VERSION ""

NS_ :

BS_:

BU_: TESTER XB_SUP_F XB_SUP_D XB_SUP_E

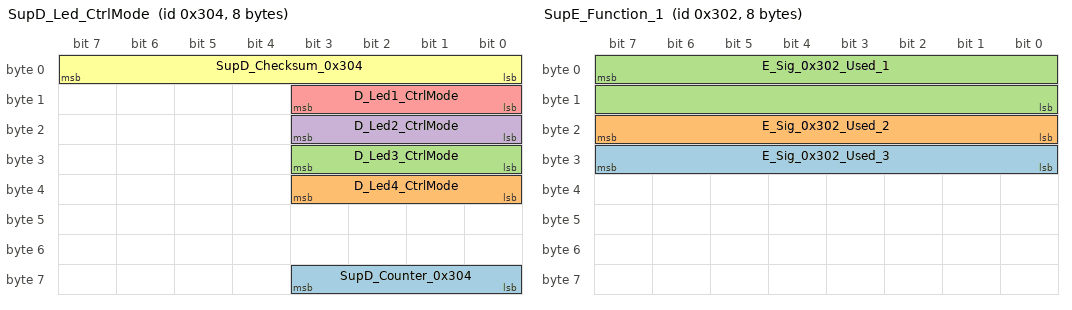
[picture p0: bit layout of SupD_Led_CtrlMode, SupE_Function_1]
BO_ 772 SupD_Led_CtrlMode: 8 XB_SUP_D
 SG_ SupD_Counter_0x304 : 59|4@0+ (1,0) [0|14] ""  XB_SUP_F
 SG_ D_Led4_CtrlMode : 35|4@0+ (1,0) [0|2] ""  XB_SUP_F
 SG_ D_Led3_CtrlMode : 27|4@0+ (1,0) [0|2] ""  XB_SUP_F
 SG_ D_Led2_CtrlMode : 19|4@0+ (1,0) [0|2] ""  XB_SUP_F
 SG_ D_Led1_CtrlMode : 11|4@0+ (1,0) [0|2] ""  XB_SUP_F
 SG_ SupD_Checksum_0x304 : 7|8@0+ (1,0) [0|255] ""  XB_SUP_F

BO_ 770 SupE_Function_1: 8 XB_SUP_E
 SG_ E_Sig_0x302_Used_3 : 31|8@0+ (1,0) [0|4095] ""  XB_SUP_F
 SG_ E_Sig_0x302_Used_2 : 23|8@0+ (1,0) [0|4095] ""  XB_SUP_F
 SG_ E_Sig_0x302_Used_1 : 7|16@0+ (1,0) [0|65535] ""  XB_SUP_F

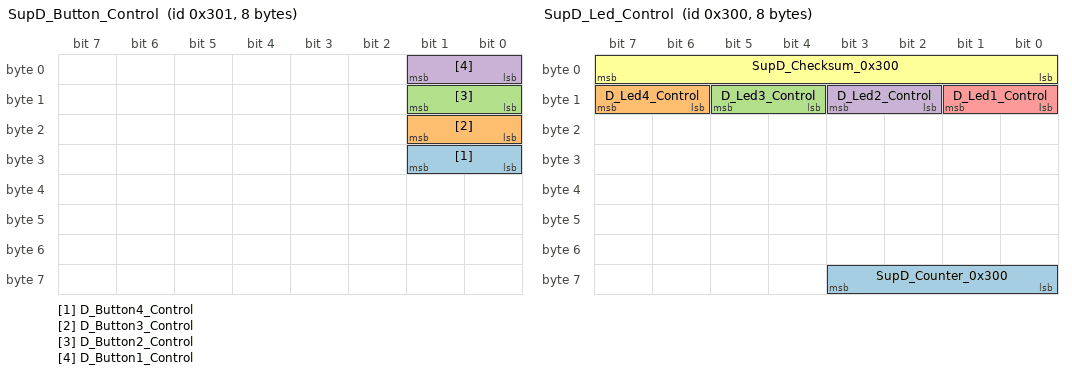
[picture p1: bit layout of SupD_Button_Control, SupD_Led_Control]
BO_ 769 SupD_Button_Control: 8 XB_SUP_D
 SG_ D_Button4_Control : 25|2@0+ (1,0) [0|2] ""  XB_SUP_F
 SG_ D_Button3_Control : 17|2@0+ (1,0) [0|2] ""  XB_SUP_F
 SG_ D_Button2_Control : 9|2@0+ (1,0) [0|2] ""  XB_SUP_F
 SG_ D_Button1_Control : 1|2@0+ (1,0) [0|2] ""  XB_SUP_F

BO_ 768 SupD_Led_Control: 8 XB_SUP_D
 SG_ SupD_Counter_0x300 : 59|4@0+ (1,0) [0|14] ""  XB_SUP_F
 SG_ D_Led4_Control : 15|2@0+ (1,0) [0|3] ""  XB_SUP_F
 SG_ D_Led3_Control : 13|2@0+ (1,0) [0|3] ""  XB_SUP_F
 SG_ D_Led2_Control : 11|2@0+ (1,0) [0|3] ""  XB_SUP_F
 SG_ D_Led1_Control : 9|2@0+ (1,0) [0|3] ""  XB_SUP_F
 SG_ SupD_Checksum_0x300 : 7|8@0+ (1,0) [0|255] ""  XB_SUP_F

BO_ 534 SupF_ComError: 8 XB_SUP_F
 SG_ F_Meg_E2E_Error : 15|8@0+ (1,0) [0|255] ""  XB_SUP_D
 SG_ F_Mes_Lost_Error : 7|8@0+ (1,0) [0|255] ""  XB_SUP_D

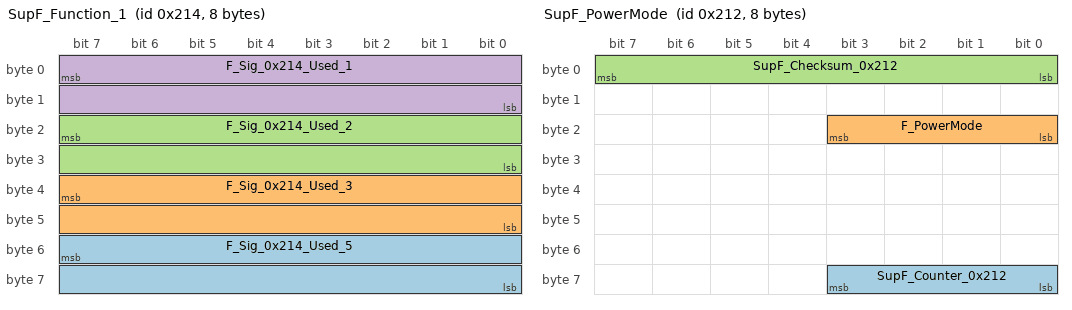
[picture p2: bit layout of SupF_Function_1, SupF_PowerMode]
BO_ 532 SupF_Function_1: 8 XB_SUP_F
 SG_ F_Sig_0x214_Used_5 : 55|16@0+ (1,0) [0|65535] ""  XB_SUP_D
 SG_ F_Sig_0x214_Used_3 : 39|16@0+ (1,0) [0|65535] ""  XB_SUP_D
 SG_ F_Sig_0x214_Used_2 : 23|16@0+ (1,0) [0|65535] ""  XB_SUP_D
 SG_ F_Sig_0x214_Used_1 : 7|16@0+ (1,0) [0|65535] ""  XB_SUP_D

BO_ 531 SupF_Angle: 8 XB_SUP_F
 SG_ F_AAA_Angle : 7|8@0+ (0.5,-10) [-10|10] "o"  XB_SUP_D

BO_ 530 SupF_PowerMode: 8 XB_SUP_F
 SG_ SupF_Counter_0x212 : 59|4@0+ (1,0) [0|14] ""  XB_SUP_D
 SG_ F_PowerMode : 19|4@0+ (1,0) [0|7] ""  XB_SUP_D
 SG_ SupF_Checksum_0x212 : 7|8@0+ (1,0) [0|255] ""  XB_SUP_D

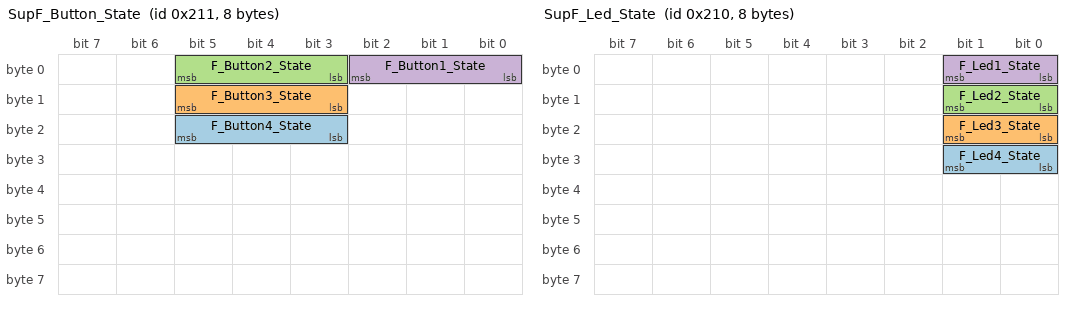
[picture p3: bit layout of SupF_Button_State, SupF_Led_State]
BO_ 529 SupF_Button_State: 8 XB_SUP_F
 SG_ F_Button4_State : 21|3@0+ (1,0) [0|7] ""  XB_SUP_D
 SG_ F_Button3_State : 13|3@0+ (1,0) [0|7] ""  XB_SUP_D
 SG_ F_Button2_State : 5|3@0+ (1,0) [0|7] ""  XB_SUP_D
 SG_ F_Button1_State : 2|3@0+ (1,0) [0|7] ""  XB_SUP_D

BO_ 528 SupF_Led_State: 8 XB_SUP_F
 SG_ F_Led4_State : 25|2@0+ (1,0) [0|3] ""  XB_SUP_D
 SG_ F_Led3_State : 17|2@0+ (1,0) [0|3] ""  XB_SUP_D
 SG_ F_Led2_State : 9|2@0+ (1,0) [0|3] ""  XB_SUP_D
 SG_ F_Led1_State : 1|2@0+ (1,0) [0|3] ""  XB_SUP_D

BO_ 1537 Meg_NmTx: 8 XB_SUP_F
 SG_ Sig_NmTx_Nid : 7|8@0+ (1,0) [0|255] ""  TESTER

BO_ 1536 Meg_NmRx: 8 TESTER
 SG_ Sig_NmRx_Nid : 7|8@0+ (1,0) [0|255] ""  XB_SUP_F

BO_ 1873 Meg_ResDiag: 8 XB_SUP_F
 SG_ Sig_ResDiag : 7|64@0+ (1,0) [0|255] ""  TESTER

BO_ 1793 Meg_PhyDiag: 8 TESTER
 SG_ Sig_PhyDiag : 7|64@0+ (1,0) [0|255] ""  XB_SUP_F

BO_ 2015 Meg_FunDiag: 8 TESTER
 SG_ Sig_FunDiag : 7|64@0+ (1,0) [0|255] ""  XB_SUP_F

BA_DEF_ BU_  "TimeQuantaCANFDMax" INT 4 257;
BA_DEF_ BU_  "TimeQuantaCANFDMin" INT 4 257;
BA_DEF_ BU_  "TimeQuantaMax" INT 4 257;
BA_DEF_ BU_  "TimeQuantaMin" INT 4 257;
BA_DEF_ BU_  "SSPOffsetCANFDMax" FLOAT 50 99.9;
BA_DEF_ BU_  "SSPOffsetCANFDMin" FLOAT 50 99.9;
BA_DEF_ BU_  "SamplePointCANFDMax" FLOAT 50 99.9;
BA_DEF_ BU_  "SamplePointCANFDMin" FLOAT 50 99.9;
BA_DEF_ BU_  "SyncJumpWidthCANFDMax" FLOAT 0 50;
BA_DEF_ BU_  "SyncJumpWidthCANFDMin" FLOAT 0 50;
BA_DEF_  "BaudrateCANFD" INT 1 16000000;
BA_DEF_ SG_  "GenSigSwitchedByIgnition" ENUM  "No","Yes";
BA_DEF_ SG_  "GenSigFuncType" ENUM  "NoFunction","MsgCounter","CRC-8","XOR","XOR-2","DatedBit","SW-Kl15","CHK","Constant","Protocol","CRC-8-SAE_J1850","CRC-32","DataLength","DataID","MsgCounter16","SOK-Signatur","Cluster";
BA_DEF_ BO_  "MsgType" ENUM  "Application","NM ","NMH","TP2.0","ISO-TP ","BAP","EID","KS","XCP_PRE_CONFIGURED","XCP_RUNTIME_CONFIGURED";
BA_DEF_ BO_  "NmhMessage" ENUM  "No","Yes";
BA_DEF_ BO_  "NmMessage" ENUM  "No","Yes";
BA_DEF_ BO_  "GenMsgNrOfRepetition" INT 0 100;
BA_DEF_ BU_  "NmStationAddress" HEX 0 127;
BA_DEF_ BU_  "NmhNode" ENUM  "No","Yes";
BA_DEF_ BU_  "ECUVariantDefault" ENUM  "No","Yes";
BA_DEF_ BU_  "GenNodAutoGenSnd" ENUM  "No","Yes";
BA_DEF_ BU_  "GenNodAutoGenDsp" ENUM  "No","Yes";
BA_DEF_  "NmhLongTimer" INT 0 65535;
BA_DEF_  "NmhPrepareBusSleepTimer" INT 0 65535;
BA_DEF_  "NmhWaitBusSleepTimer" INT 0 65535;
BA_DEF_  "NmhTimeoutTimer" INT 0 65535;
BA_DEF_  "NBTMax" INT 1 30;
BA_DEF_  "NBTMin" INT 1 30;
BA_DEF_  "SyncJumpWidthMax" INT 1 4;
BA_DEF_  "SyncJumpWidthMin" INT 1 4;
BA_DEF_  "SamplePointMax" INT 1 100;
BA_DEF_  "SamplePointMin" INT 1 100;
BA_DEF_  "Baudrate" INT 1 1000000;
BA_DEF_  "VersionYear" INT 0 99;
BA_DEF_  "VersionWeek" INT 1 52;
BA_DEF_  "VersionMonth" INT 1 12;
BA_DEF_  "VersionDay" INT 1 31;
BA_DEF_  "NmhMessageCount" INT 0 1024;
BA_DEF_  "NmhBaseAddress" HEX 1536 1663;
BA_DEF_  "Manufacturer" STRING ;
BA_DEF_  "DBName" STRING ;
BA_DEF_  "BusType" STRING ;
BA_DEF_  "GenEnvVarEndingDsp" STRING ;
BA_DEF_  "GenEnvVarEndingSnd" STRING ;
BA_DEF_  "GenEnvVarPrefix" STRING ;
BA_DEF_  "GenNWMApBusSleep" STRING ;
BA_DEF_  "GenNWMApCanNormal" STRING ;
BA_DEF_  "GenNWMApCanOff" STRING ;
BA_DEF_  "GenNWMApCanOn" STRING ;
BA_DEF_  "GenNWMApCanSleep" STRING ;
BA_DEF_  "GenNWMApCanWakeUp" STRING ;
BA_DEF_  "GenNWMGotoMode_Awake" STRING ;
BA_DEF_  "GenNWMGotoMode_BusSleep" STRING ;
BA_DEF_  "GenNWMTalkNM" STRING ;
BA_DEF_ BU_  "NodeLayerModules" STRING ;
BA_DEF_ BU_  "ILUsed" ENUM  "No","Yes";
BA_DEF_ BO_  "DiagState" ENUM  "No","Yes";
BA_DEF_ BO_  "DiagResponse" ENUM  "No","Yes";
BA_DEF_ BO_  "DiagRequest" ENUM  "No","Yes";
BA_DEF_ BO_  "GenMsgILSupport" ENUM  "No","Yes";
BA_DEF_ BO_  "GenMsgCycleTime" INT 0 65535;
BA_DEF_ BO_  "GenMsgMinAcceptLength" INT 0 8;
BA_DEF_ BO_  "GenMsgSendType" ENUM  "Cyclic","CyclicAndSpontanX","Event";
BA_DEF_ BO_  "CANFD_BRS" ENUM  "0","1";
BA_DEF_ BO_  "VFrameFormat" ENUM  "StandardCAN","ExtendedCAN","reserved","reserved","reserved","reserved","reserved","reserved","reserved","reserved","reserved","reserved","reserved","reserved","StandardCAN_FD","ExtendedCAN_FD";
BA_DEF_ SG_  "GenSigEnvVarType" ENUM  "undef","int","float";
BA_DEF_ SG_  "GenSigSendType" ENUM  "Cyclic","OnWrite","OnWriteWithRepetition","OnChange","OnChangeWithRepetition","IfActive","IfActiveWithRepetition","NoSigSendType","NotUsed","NotUsed","NotUsed","NotUsed","NotUsed";
BA_DEF_ SG_  "GenSigStartValue" FLOAT 0 1215752192;
BA_DEF_DEF_  "TimeQuantaCANFDMax" 40;
BA_DEF_DEF_  "TimeQuantaCANFDMin" 40;
BA_DEF_DEF_  "TimeQuantaMax" 160;
BA_DEF_DEF_  "TimeQuantaMin" 160;
BA_DEF_DEF_  "SSPOffsetCANFDMax" 75;
BA_DEF_DEF_  "SSPOffsetCANFDMin" 75;
BA_DEF_DEF_  "SamplePointCANFDMax" 75;
BA_DEF_DEF_  "SamplePointCANFDMin" 75;
BA_DEF_DEF_  "SyncJumpWidthCANFDMax" 50;
BA_DEF_DEF_  "SyncJumpWidthCANFDMin" 50;
BA_DEF_DEF_  "BaudrateCANFD" 2000000;
BA_DEF_DEF_  "GenSigSwitchedByIgnition" "Yes";
BA_DEF_DEF_  "GenSigFuncType" "NoFunction";
BA_DEF_DEF_  "MsgType" "Application";
BA_DEF_DEF_  "NmhMessage" "No";
BA_DEF_DEF_  "NmMessage" "No";
BA_DEF_DEF_  "GenMsgNrOfRepetition" 0;
BA_DEF_DEF_  "NmStationAddress" 0;
BA_DEF_DEF_  "NmhNode" "Yes";
BA_DEF_DEF_  "ECUVariantDefault" "Yes";
BA_DEF_DEF_  "GenNodAutoGenSnd" "Yes";
BA_DEF_DEF_  "GenNodAutoGenDsp" "Yes";
BA_DEF_DEF_  "NmhLongTimer" 0;
BA_DEF_DEF_  "NmhPrepareBusSleepTimer" 2000;
BA_DEF_DEF_  "NmhWaitBusSleepTimer" 5000;
BA_DEF_DEF_  "NmhTimeoutTimer" 2000;
BA_DEF_DEF_  "NBTMax" 20;
BA_DEF_DEF_  "NBTMin" 10;
BA_DEF_DEF_  "SyncJumpWidthMax" 1;
BA_DEF_DEF_  "SyncJumpWidthMin" 1;
BA_DEF_DEF_  "SamplePointMax" 1;
BA_DEF_DEF_  "SamplePointMin" 1;
BA_DEF_DEF_  "Baudrate" 500000;
BA_DEF_DEF_  "VersionYear" 19;
BA_DEF_DEF_  "VersionWeek" 45;
BA_DEF_DEF_  "VersionMonth" 11;
BA_DEF_DEF_  "VersionDay" 8;
BA_DEF_DEF_  "NmhMessageCount" 1;
BA_DEF_DEF_  "NmhBaseAddress" 1536;
BA_DEF_DEF_  "Manufacturer" "GWM";
BA_DEF_DEF_  "DBName" "V51EV_for_PT_CANFD V1_0婵炲瓨鍤庨崐鏍绮婇敃鍌涘亱";
BA_DEF_DEF_  "BusType" "";
BA_DEF_DEF_  "GenEnvVarEndingDsp" "_d";
BA_DEF_DEF_  "GenEnvVarEndingSnd" "_s";
BA_DEF_DEF_  "GenEnvVarPrefix" "c";
BA_DEF_DEF_  "GenNWMApBusSleep" "apBusSleep()";
BA_DEF_DEF_  "GenNWMApCanNormal" "apCanNormal()";
BA_DEF_DEF_  "GenNWMApCanOff" "apCanOff()";
BA_DEF_DEF_  "GenNWMApCanOn" "apCanOn()";
BA_DEF_DEF_  "GenNWMApCanSleep" "apCanSleep()";
BA_DEF_DEF_  "GenNWMApCanWakeUp" "apCanWakeUp()";
BA_DEF_DEF_  "GenNWMGotoMode_Awake" "GotoMode_Awake()";
BA_DEF_DEF_  "GenNWMGotoMode_BusSleep" "GotoMode_BusSleep()";
BA_DEF_DEF_  "GenNWMTalkNM" "TalkNM()";
BA_DEF_DEF_  "NodeLayerModules" "CANoeILNLVector.dll";
BA_DEF_DEF_  "ILUsed" "Yes";
BA_DEF_DEF_  "DiagState" "No";
BA_DEF_DEF_  "DiagResponse" "No";
BA_DEF_DEF_  "DiagRequest" "No";
BA_DEF_DEF_  "GenMsgILSupport" "Yes";
BA_DEF_DEF_  "GenMsgCycleTime" 10;
BA_DEF_DEF_  "GenMsgMinAcceptLength" 8;
BA_DEF_DEF_  "GenMsgSendType" "Cyclic";
BA_DEF_DEF_  "CANFD_BRS" "1";
BA_DEF_DEF_  "VFrameFormat" "StandardCAN";
BA_DEF_DEF_  "GenSigEnvVarType" "undef";
BA_DEF_DEF_  "GenSigSendType" "Cyclic";
BA_DEF_DEF_  "GenSigStartValue" 0;
BA_ "BusType" "CAN";
BA_ "NmhMessageCount" 256;
BA_ "SyncJumpWidthMin" 2;
BA_ "SyncJumpWidthMax" 4;
BA_ "NmhWaitBusSleepTimer" 2000;
BA_ "NmhPrepareBusSleepTimer" 100;
BA_ "NmhLongTimer" 200;
BA_ "DBName" "DBCNetWork";
BA_ "NmStationAddress" BU_ XB_SUP_F 1;
BA_ "GenMsgNrOfRepetition" BO_ 532 3;
BA_ "GenMsgSendType" BO_ 532 2;
BA_ "GenMsgCycleTime" BO_ 532 20;
BA_ "GenMsgCycleTime" BO_ 530 100;
BA_ "GenMsgCycleTime" BO_ 529 50;
BA_ "GenMsgCycleTime" BO_ 528 100;
BA_ "GenMsgILSupport" BO_ 1537 0;
BA_ "NmMessage" BO_ 1537 1;
BA_ "MsgType" BO_ 1537 1;
BA_ "GenMsgSendType" BO_ 1537 2;
BA_ "GenMsgCycleTime" BO_ 1537 0;
BA_ "NmhMessage" BO_ 1537 1;
BA_ "GenMsgILSupport" BO_ 1536 0;
BA_ "NmMessage" BO_ 1536 1;
BA_ "MsgType" BO_ 1536 1;
BA_ "GenMsgSendType" BO_ 1536 2;
BA_ "GenMsgCycleTime" BO_ 1536 0;
BA_ "NmhMessage" BO_ 1536 1;
BA_ "GenMsgILSupport" BO_ 1873 0;
BA_ "DiagResponse" BO_ 1873 1;
BA_ "MsgType" BO_ 1873 4;
BA_ "GenMsgSendType" BO_ 1873 2;
BA_ "GenMsgCycleTime" BO_ 1873 0;
BA_ "GenMsgILSupport" BO_ 1793 0;
BA_ "DiagRequest" BO_ 1793 1;
BA_ "MsgType" BO_ 1793 4;
BA_ "GenMsgSendType" BO_ 1793 2;
BA_ "GenMsgCycleTime" BO_ 1793 0;
BA_ "GenMsgILSupport" BO_ 2015 0;
BA_ "DiagState" BO_ 2015 1;
BA_ "MsgType" BO_ 2015 4;
BA_ "GenMsgSendType" BO_ 2015 2;
BA_ "GenMsgCycleTime" BO_ 2015 0;
BA_ "GenSigStartValue" SG_ 768 D_Led4_Control 2;
BA_ "GenSigStartValue" SG_ 768 D_Led3_Control 2;
BA_ "GenSigStartValue" SG_ 768 D_Led2_Control 2;
BA_ "GenSigStartValue" SG_ 768 D_Led1_Control 2;
BA_ "GenSigStartValue" SG_ 531 F_AAA_Angle 36;
VAL_ 772 D_Led4_CtrlMode 0 "Can_Control" 1 "Button_Control_Mode1" 2 "Button_Control_Mode2" 3 "Reserve" ;
VAL_ 772 D_Led3_CtrlMode 0 "Can_Control" 1 "Button_Control_Mode1" 2 "Button_Control_Mode2" 3 "Reserve" ;
VAL_ 772 D_Led2_CtrlMode 0 "Can_Control" 1 "Button_Control_Mode1" 2 "Button_Control_Mode2" 3 "Reserve" ;
VAL_ 772 D_Led1_CtrlMode 0 "Can_Control" 1 "Button_Control_Mode1" 2 "Button_Control_Mode2" 3 "Reserve" ;
VAL_ 769 D_Button4_Control 0 "Button_Mode1" 1 "Button_Mode2" 2 "Button_Disable" ;
VAL_ 769 D_Button3_Control 0 "Button_Mode1" 1 "Button_Mode2" 2 "Button_Disable" ;
VAL_ 769 D_Button2_Control 0 "Button_Mode1" 1 "Button_Mode2" 2 "Button_Disable" ;
VAL_ 769 D_Button1_Control 0 "Button_Mode1" 1 "Button_Mode2" 2 "Button_Disable" ;
VAL_ 768 D_Led4_Control 0 "Init" 1 "LED_ON" 2 "LED_OFF" 3 "Reserve" ;
VAL_ 768 D_Led3_Control 0 "Init" 1 "LED_ON" 2 "LED_OFF" 3 "Reserve" ;
VAL_ 768 D_Led2_Control 0 "Init" 1 "LED_ON" 2 "LED_OFF" 3 "Reserve" ;
VAL_ 768 D_Led1_Control 0 "Init" 1 "LED_ON" 2 "LED_OFF" 3 "Reserve" ;
VAL_ 534 F_Meg_E2E_Error 0 "No E2E Error" 1 "Message 0x301 E2E Error" 2 "Message 0x304 E2E Error" ;
VAL_ 534 F_Mes_Lost_Error 0 "No Message Lost" 1 "Message 0x300 Lost" 2 "Message 0x301 Lost" 3 "Message 0x302 Lost" 4 "Message 0x303 Lost" 5 "Message 0x304 Lost" ;
VAL_ 530 F_PowerMode 0 "OFF" 1 "ON" 2 "Reserve" ;
VAL_ 529 F_Button4_State 0 "Button_Push" 1 "Button_Release" 2 "Reserve" ;
VAL_ 529 F_Button3_State 0 "Button_Push" 1 "Button_Release" 2 "Reserve" ;
VAL_ 529 F_Button2_State 0 "Button_Push" 1 "Button_Release" 2 "Reserve" ;
VAL_ 529 F_Button1_State 0 "Button_Push" 1 "Button_Release" 2 "Reserve" ;
VAL_ 528 F_Led4_State 0 "LED_ON" 1 "LED_OFF" 2 "Reserve" 3 "Reserve" ;
VAL_ 528 F_Led3_State 0 "LED_ON" 1 "LED_OFF" 2 "Reserve" 3 "Reserve" ;
VAL_ 528 F_Led2_State 0 "LED_ON" 1 "LED_OFF" 2 "Reserve" 3 "Reserve" ;
VAL_ 528 F_Led1_State 0 "LED_ON" 1 "LED_OFF" 2 "Reserve" 3 "Reserve" ;
SIG_GROUP_ 772 Sig_Grp_0x304 1 : SupD_Checksum_0x304 D_Led1_CtrlMode D_Led2_CtrlMode D_Led3_CtrlMode D_Led4_CtrlMode SupD_Counter_0x304;
SIG_GROUP_ 770 Sig_Grp_0x302 1 : E_Sig_0x302_Used_1 E_Sig_0x302_Used_2 E_Sig_0x302_Used_3;
SIG_GROUP_ 769 Sig_Grp_0x301 1 : D_Button1_Control D_Button2_Control D_Button3_Control D_Button4_Control;
SIG_GROUP_ 768 Sig_Grp_0x300 1 : SupD_Checksum_0x300 D_Led1_Control D_Led2_Control D_Led3_Control D_Led4_Control SupD_Counter_0x300;
SIG_GROUP_ 534 Sig_Grp_0x216 1 : F_Mes_Lost_Error F_Meg_E2E_Error;
SIG_GROUP_ 532 Sig_Grp_0x214 1 : F_Sig_0x214_Used_1 F_Sig_0x214_Used_2 F_Sig_0x214_Used_3 F_Sig_0x214_Used_5;
SIG_GROUP_ 531 Sig_Grp_0x213 1 : F_AAA_Angle;
SIG_GROUP_ 530 Sig_Grp_0x212 1 : SupF_Checksum_0x212 F_PowerMode SupF_Counter_0x212;
SIG_GROUP_ 529 Sig_Grp_0x211 1 : F_Button1_State F_Button2_State F_Button3_State F_Button4_State;
SIG_GROUP_ 528 Sig_Grp_0x210 1 : F_Led1_State F_Led2_State F_Led3_State F_Led4_State;
